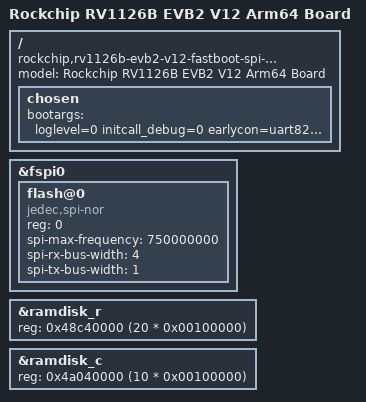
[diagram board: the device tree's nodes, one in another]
// SPDX-License-Identifier: (GPL-2.0+ OR MIT)
/*
 * Copyright (c) 2025 Rockchip Electronics Co., Ltd.
 */

/dts-v1/;
#include "rv1126b-evb2-v12.dts"
#include "rv1126b-fastboot-spi-nor.dtsi"

/ {
	model = "Rockchip RV1126B EVB2 V12 Arm64 Board";
	compatible = "rockchip,rv1126b-evb2-v12-fastboot-spi-nor", "rockchip,rv1126b";

	chosen {
		bootargs = "loglevel=0 initcall_debug=0 earlycon=uart8250,mmio32,0x20810000 console=ttyFIQ0 root=/dev/rd0 rootfstype=erofs rootflags=dax snd_soc_core.prealloc_buffer_size_kbytes=16 coherent_pool=32K";
	};
};

&fspi0 {
	status = "okay";

	flash@0 {
		compatible = "jedec,spi-nor";
		reg = <0>;
		spi-max-frequency = <750000000>;
		spi-rx-bus-width = <4>;
		spi-tx-bus-width = <1>;
	};
};

&ramdisk_r {
	reg = <0x48c40000 (20 * 0x00100000)>;
};

&ramdisk_c {
	reg = <0x4a040000 (10 * 0x00100000)>;
};
